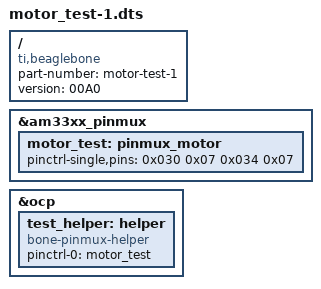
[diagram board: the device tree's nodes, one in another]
/* Device Tree Overlay for motor_test
 * 
 * Copyright (C) 2012 Texas Instruments Incorporated - http://www.ti.com/
 *
 * This program is free software; you can redistribute it and/or modify
 * it under the terms of the GNU General Purpose License Version 2 as
 * published by the Free Software Foundation
 *
 * Original from: github.com/jadonk/validation-scripts/blob/master/test-capemgr/ 
 * 
 */

/dts-v1/;
/plugin/;

/ {
        compatible = "ti,beaglebone", "ti,beaglebone-black";

        part-number = "motor-test-1";
        version = "00A0";
        
        fragment@0 {
                target = <&am33xx_pinmux>;
                __overlay__ {
                        motor_test: pinmux_motor {
                                pinctrl-single,pins = <
                                 0x030 0x07  /* P8_12 44 OUTPUT  MODE7 */
                                 0x034 0x07  /* P8_13 45 OUTPUT  MODE7 */
                       
                                 /* OUTPUT  GPIO(mode7) 0x07 pulldown, 0x17 pullup, 0x?f no pullup/down */
                                 /* INPUT   GPIO(mode7) 0x27 pulldown, 0x37 pullup, 0x?f no pullup/down */
                                                      >;
                        };
                };
        };

        fragment@1 {
                target = <&ocp>;
                __overlay__ {
                        test_helper: helper {
                                compatible = "bone-pinmux-helper";
                                pinctrl-names = "default";
                                pinctrl-0 = <&motor_test>;
                                status = "okay";
                        };
                };
        };
};
